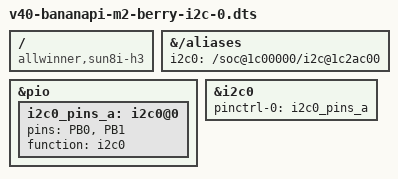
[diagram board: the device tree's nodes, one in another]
/dts-v1/;
/plugin/;

/ {
	compatible = "allwinner,sun8i-h3";

	fragment@0 {
		target-path = "/aliases";
		__overlay__ {
			i2c0 = "/soc@1c00000/i2c@1c2ac00";
		};
	};

	fragment@1 {
		target = <&pio>;
		__overlay__ {
			i2c0_pins_a: i2c0@0 {
				pins = "PB0", "PB1";
				function = "i2c0";
			};
		};
	};

	fragment@2 {
		target = <&i2c0>;
		__overlay__ {
			pinctrl-names = "default";
			pinctrl-0 = <&i2c0_pins_a>;
			status = "okay";
		};
	};
};
